# CC1314R10 register map
File version: 1.0
CPU: CM33 1.0, other endian, MPU, FPU, 3 interrupt priority bits
Registers are 32-bit, read-write, reset 0x0 unless marked. A register's access mark holds for its fields unless they carry their own. Offsets are from the block's base; [hi:lo] are bit positions; {n}, {i} and the like mark numbered series; 'fields as' and 'values as' point back to an identical list.

## CPU_MPU — Cortex-M's Memory Protection Unit (MPU)
Base 0xE000ED90
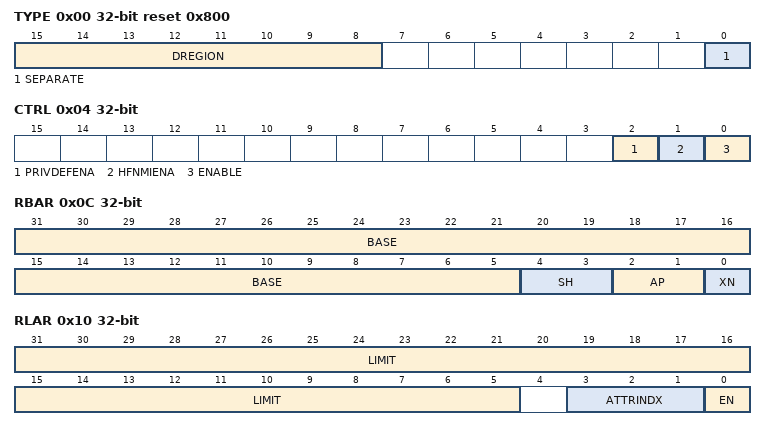
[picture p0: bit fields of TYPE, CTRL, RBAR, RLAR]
0x00 TYPE reset 0x800 — The MPU Type Register indicates how many regions the MPU supports
  [15:8] DREGION ro — [15:8] Number of regions supported by the MPU
  [0] SEPARATE ro — [0:0] Indicates support for separate instructions and data address regions
0x04 CTRL — Enables the MPU and, when the MPU is enabled, controls whether the default memory map is enabled as a background region for privileged accesses, and whether the MPU is enabled for HardFaults, NMIs, and exception handlers when FAULTMASK is set to 1
  [2] PRIVDEFENA — [2:2] Controls whether the default memory map is enabled for privileged software
  [1] HFNMIENA — [1:1] Controls whether handlers executing with priority less than 0 access memory with the MPU enabled or disabled. This applies to HardFaults, NMIs, and exception handlers when FAULTMASK is set to 1
  [0] ENABLE — [0:0] Enables the MPU
0x08 RNR — Selects the region currently accessed by MPU_RBAR and MPU_RLAR
  [7:0] REGION — [7:0] Indicates the memory region accessed by MPU_RBAR and MPU_RLAR
0x0C RBAR — Provides indirect read and write access to the base address of the currently selected MPU region
  [31:5] BASE — [31:5] Contains bits [31:5] of the lower inclusive limit of the selected MPU memory region. This value is zero extended to provide the base address to be checked against
  [4:3] SH — [4:3] Defines the Shareability domain of this region for Normal memory
  [2:1] AP — [2:1] Defines the access permissions for this region
  [0] XN — [0:0] Defines whether code can be executed from this region
0x10 RLAR — Provides indirect read and write access to the limit address of the currently selected MPU region
  [31:5] LIMIT — [31:5] Contains bits [31:5] of the upper inclusive limit of the selected MPU memory region. This value is postfixed with 0x1F to provide the limit address to be checked against
  [3:1] ATTRINDX — [3:1] Associates a set of attributes in the MPU_MAIR0 and MPU_MAIR1 fields
  [0] EN — [0:0] Region enable
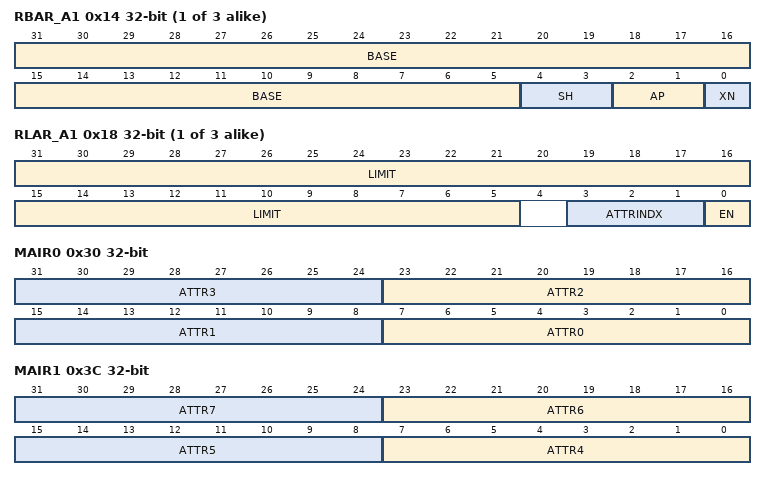
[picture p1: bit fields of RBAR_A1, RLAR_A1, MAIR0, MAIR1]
{0xC+8i} RBAR_A{i} (i=1..3) — Provides indirect read and write access to the base address of the MPU region selected by MPU_RNR[7:2]:({i}[1:0])
  fields as RBAR
{0x10+8i} RLAR_A{i} (i=1..3) — Provides indirect read and write access to the limit address of the currently selected MPU region selected by MPU_RNR[7:2]:({i}[1:0])
  fields as RLAR
0x30 MAIR0 — Along with MPU_MAIR1, provides the memory attribute encodings corresponding to the AttrIndex values
  [8n+7:8n] ATTR{n} (n=0..3) — [{8n+7}:{8n}] Memory attribute encoding for MPU regions with an AttrIndex of {n}
0x3C MAIR1 — Along with MPU_MAIR0, provides the memory attribute encodings corresponding to the AttrIndex values
  [8n-25:8n-32] ATTR{n} (n=4..7) — [{8n-25}:{8n-32}] Memory attribute encoding for MPU regions with an AttrIndex of {n}

## CPU_SAU — Cortex-M's Security Attribution Unit (SAU)
Base 0xE000EDD0
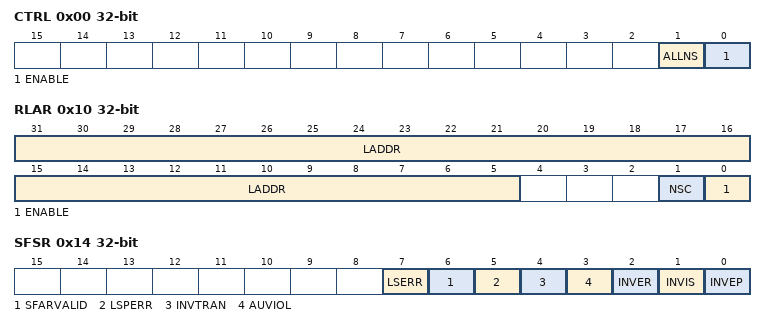
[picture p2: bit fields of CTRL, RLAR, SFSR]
0x00 CTRL — Allows enabling of the Security Attribution Unit
  [1] ALLNS — [1:1] When SAU_CTRL.ENABLE is 0 this bit controls if the memory is marked as Non-secure or Secure
  [0] ENABLE — [0:0] Enables the SAU
0x04 TYPE — Indicates the number of regions implemented by the Security Attribution Unit
  [7:0] SREGION ro — [7:0] The number of implemented SAU regions
0x08 RNR — Selects the region currently accessed by SAU_RBAR and SAU_RLAR
  [7:0] REGION — [7:0] Indicates the SAU region accessed by SAU_RBAR and SAU_RLAR
0x0C RBAR — Provides indirect read and write access to the base address of the currently selected SAU region
  [31:5] BADDR — [31:5] Holds bits [31:5] of the base address for the selected SAU region
0x10 RLAR — Provides indirect read and write access to the limit address of the currently selected SAU region
  [31:5] LADDR — [31:5] Holds bits [31:5] of the limit address for the selected SAU region
  [1] NSC — [1:1] Controls whether Non-secure state is permitted to execute an SG instruction from this region
  [0] ENABLE — [0:0] SAU region enable
0x14 SFSR — Provides information about any security related faults
  [7] LSERR — [7:7] Sticky flag indicating that an error occurred during lazy state activation or deactivation
  [6] SFARVALID — [6:6] This bit is set when the SFAR register contains a valid value. As with similar fields, such as BFSR.BFARVALID and MMFSR.MMARVALID, this bit can be cleared by other exceptions, such as BusFault
  [5] LSPERR — [5:5] Stick flag indicating that an SAU or IDAU violation occurred during the lazy preservation of floating-point state
  [4] INVTRAN — [4:4] Sticky flag indicating that an exception was raised due to a branch that was not flagged as being domain crossing causing a transition from Secure to Non-secure memory
  [3] AUVIOL — [3:3] Sticky flag indicating that an attempt was made to access parts of the address space that are marked as Secure with NS-Req for the transaction set to Non-secure. This bit is not set if the violation occurred during lazy state preservation. See LSPERR
  [2] INVER — [2:2] This can be caused by EXC_RETURN.DCRS being set to 0 when returning from an exception in the Non-secure state, or by EXC_RETURN.ES being set to 1 when returning from an exception in the Non-secure state
  [1] INVIS — [1:1] This bit is set if the integrity signature in an exception stack frame is found to be invalid during the unstacking operation
  [0] INVEP — [0:0] This bit is set if a function call from the Non-secure state or exception targets a non-SG instruction in the Secure state. This bit is also set if the target address is a SG instruction, but there is no matching SAU/IDAU region with the NSC flag set
0x18 SFAR — Shows the address of the memory location that caused a Security violation
  [31:0] ADDRESS — [31:0] The address of an access that caused a attribution unit violation. This field is only valid when SFSR.SFARVALID is set. This allows the actual flip flops associated with this register to be shared with other fault address registers. If an implementation chooses to share the storage in this way, care must be taken to not leak Secure address information to the Non-secure state. One way of achieving this is to share the SFAR register with the MMFAR_S register, which is not accessible to the Non-secure state

## CPU_SIG — Cortex-M's Software Interrupt Generator (SIG)
Base 0xE000EF00
0x00 STIR — Provides a mechanism for software to generate an interrupt
  [8:0] INTID wo — [8:0] Indicates the interrupt to be pended. The value written is (ExceptionNumber - 16)
